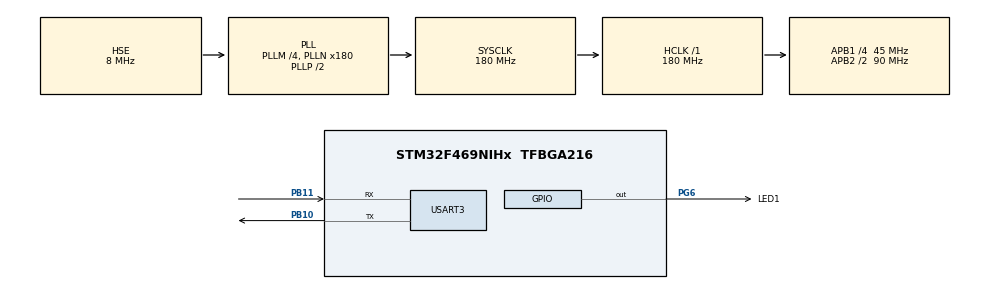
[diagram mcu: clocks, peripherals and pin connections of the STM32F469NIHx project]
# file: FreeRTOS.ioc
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FREERTOS.Tasks01=LEDTask,0,256,StartLEDTask,Default,NULL,Dynamic,NULL,NULL;Task_Info,0,512,StartTask_Info,Default,NULL,Dynamic,NULL,NULL
FREERTOS.configENABLE_BACKWARD_COMPATIBILITY=0
FREERTOS.configGENERATE_RUN_TIME_STATS=1
FREERTOS.configIDLE_SHOULD_YIELD=0
FREERTOS.configQUEUE_REGISTRY_SIZE=0
FREERTOS.configUSE_MUTEXES=0
FREERTOS.configUSE_STATS_FORMATTING_FUNCTIONS=1
FREERTOS.configUSE_TRACE_FACILITY=1
Mcu.Family=STM32F4
Mcu.Name=STM32F469NIHx
Mcu.Package=TFBGA216
NVIC.PriorityGroup=NVIC_PRIORITYGROUP_4
NVIC.TIM6_DAC_IRQn=true\:0\:0\:false\:false\:true\:false\:false
NVIC.TIM7_IRQn=true\:1\:0\:true\:true\:true\:1\:false\:true
NVIC.TimeBase=TIM6_DAC_IRQn
NVIC.TimeBaseIP=TIM6
PA13.Mode=Serial_Wire
PA13.Signal=SYS_JTMS-SWDIO
PA14.Mode=Serial_Wire
PA14.Signal=SYS_JTCK-SWCLK
PB10.Mode=Asynchronous
PB10.Signal=USART3_TX
PB11.Mode=Asynchronous
PB11.Signal=USART3_RX
PC14/OSC32_IN.Mode=LSE-External-Oscillator
PC14/OSC32_IN.Signal=RCC_OSC32_IN
PC15/OSC32_OUT.Mode=LSE-External-Oscillator
PC15/OSC32_OUT.Signal=RCC_OSC32_OUT
PG6.GPIO_Label=LED1
PG6.GPIO_Speed=GPIO_SPEED_FREQ_VERY_HIGH
PG6.Signal=GPIO_Output
PH0/OSC_IN.Mode=HSE-External-Oscillator
PH0/OSC_IN.Signal=RCC_OSC_IN
PH1/OSC_OUT.Mode=HSE-External-Oscillator
PH1/OSC_OUT.Signal=RCC_OSC_OUT
ProjectManager.HeapSize=0x800
ProjectManager.StackSize=0x1000
ProjectManager.TargetToolchain=MDK-ARM V5
RCC.AHBFreq_Value=180000000
RCC.APB1CLKDivider=RCC_HCLK_DIV4
RCC.APB1Freq_Value=45000000
RCC.APB1TimFreq_Value=90000000
RCC.APB2CLKDivider=RCC_HCLK_DIV2
RCC.APB2Freq_Value=90000000
RCC.APB2TimFreq_Value=180000000
RCC.CortexFreq_Value=180000000
RCC.HCLKFreq_Value=180000000
RCC.HSE_VALUE=8000000
RCC.PLLDSIIDF=DSI_PLL_IN_DIV2
RCC.PLLDSINDIV=125
RCC.PLLM=4
RCC.PLLN=180
RCC.PLLQ=6
RCC.PLLR=6
RCC.PLLSAIN=144
RCC.PLLSAIP=RCC_PLLSAIP_DIV6
RCC.PLLSAIQ=2
RCC.PLLSAIRDiv=RCC_PLLSAIDIVR_4
RCC.PLLSourceVirtual=RCC_PLLSOURCE_HSE
RCC.SYSCLKFreq_VALUE=180000000
RCC.SYSCLKSource=RCC_SYSCLKSOURCE_PLLCLK
RCC.USBCLockSelection=RCC_CLK48CLKSOURCE_PLLSAIP
RCC.USBFreq_Value=48000000
RCC.VCOOutputFreq_Value=360000000
TIM7.Period=100
TIM7.Prescaler=18-1
USART3.VirtualMode=VM_ASYNC
VP_FREERTOS_VS_ENABLE.Mode=Enabled
VP_SYS_VS_tim6.Mode=TIM6
VP_TIM7_VS_ClockSourceINT.Mode=Enable_Timer
board=32F469IDISCOVERY

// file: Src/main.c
/**
  ******************************************************************************
  * @file           : main.c
  * @brief          : Main program body
  ******************************************************************************
  * This notice applies to any and all portions of this file
  * that are not between comment pairs USER CODE BEGIN and
  * USER CODE END. Other portions of this file, whether
  * inserted by the user or by software development tools
  * are owned by their respective copyright owners.
  *
  * Copyright (c) 2018 STMicroelectronics International N.V.
  * All rights reserved.
  *
  * Redistribution and use in source and binary forms, with or without
  * modification, are permitted, provided that the following conditions are met:
  *
  * 1. Redistribution of source code must retain the above copyright notice,
  *    this list of conditions and the following disclaimer.
  * 2. Redistributions in binary form must reproduce the above copyright notice,
  *    this list of conditions and the following disclaimer in the documentation
  *    and/or other materials provided with the distribution.
  * 3. Neither the name of STMicroelectronics nor the names of other
  *    contributors to this software may be used to endorse or promote products
  *    derived from this software without specific written permission.
  * 4. This software, including modifications and/or derivative works of this
  *    software, must execute solely and exclusively on microcontroller or
  *    microprocessor devices manufactured by or for STMicroelectronics.
  * 5. Redistribution and use of this software other than as permitted under
  *    this license is void and will automatically terminate your rights under
  *    this license.
  *
  * THIS SOFTWARE IS PROVIDED BY STMICROELECTRONICS AND CONTRIBUTORS "AS IS"
  * AND ANY EXPRESS, IMPLIED OR STATUTORY WARRANTIES, INCLUDING, BUT NOT
  * LIMITED TO, THE IMPLIED WARRANTIES OF MERCHANTABILITY, FITNESS FOR A
  * PARTICULAR PURPOSE AND NON-INFRINGEMENT OF THIRD PARTY INTELLECTUAL PROPERTY
  * RIGHTS ARE DISCLAIMED TO THE FULLEST EXTENT PERMITTED BY LAW. IN NO EVENT
  * SHALL STMICROELECTRONICS OR CONTRIBUTORS BE LIABLE FOR ANY DIRECT, INDIRECT,
  * INCIDENTAL, SPECIAL, EXEMPLARY, OR CONSEQUENTIAL DAMAGES (INCLUDING, BUT NOT
  * LIMITED TO, PROCUREMENT OF SUBSTITUTE GOODS OR SERVICES; LOSS OF USE, DATA,
  * OR PROFITS; OR BUSINESS INTERRUPTION) HOWEVER CAUSED AND ON ANY THEORY OF
  * LIABILITY, WHETHER IN CONTRACT, STRICT LIABILITY, OR TORT (INCLUDING
  * NEGLIGENCE OR OTHERWISE) ARISING IN ANY WAY OUT OF THE USE OF THIS SOFTWARE,
  * EVEN IF ADVISED OF THE POSSIBILITY OF SUCH DAMAGE.
  *
  ******************************************************************************
  */
#include "main.h"
#include "stm32f4xx_hal.h"
#include "cmsis_os.h"

TIM_HandleTypeDef htim7;

UART_HandleTypeDef huart3;

osThreadId LEDTaskHandle;
osThreadId Task_InfoHandle;

/* USER CODE BEGIN PV */
/* Private variables ---------------------------------------------------------*/
extern volatile uint32_t ulHighFrequencyTimerTicks ;
/* USER CODE END PV */

void SystemClock_Config(void);
static void MX_GPIO_Init(void);
void MX_TIM7_Init(void);
static void MX_USART3_UART_Init(void);
void StartLEDTask(void const * argument);
void StartTask_Info(void const * argument);
static void MX_NVIC_Init(void);

/* USER CODE BEGIN PFP */
/* Private function prototypes -----------------------------------------------*/
#ifdef __GNUC__
/* With GCC, small printf (option LD Linker->Libraries->Small printf
   set to 'Yes') calls __io_putchar() */
#define PUTCHAR_PROTOTYPE int __io_putchar(int ch)
#else
#define PUTCHAR_PROTOTYPE int fputc(int ch, FILE *f)
#endif /* __GNUC__ */
/* USER CODE END PFP */

int main(void)
{

  /* MCU Configuration----------------------------------------------------------*/

  /* Reset of all peripherals, Initializes the Flash interface and the Systick. */
  HAL_Init();

  /* Configure the system clock */
  SystemClock_Config();

  /* Initialize all configured peripherals */
  MX_GPIO_Init();
  MX_TIM7_Init();
  MX_USART3_UART_Init();

  /* Initialize interrupts */
  MX_NVIC_Init();
  /* USER CODE BEGIN 2 */
  HAL_TIM_Base_Start_IT(&htim7);
  /* USER CODE END 2 */

  /* Create the thread(s) */
  /* definition and creation of LEDTask */
  osThreadDef(LEDTask, StartLEDTask, osPriorityNormal, 0, 256);
  LEDTaskHandle = osThreadCreate(osThread(LEDTask), NULL);

  /* definition and creation of Task_Info */
  osThreadDef(Task_Info, StartTask_Info, osPriorityNormal, 0, 512);
  Task_InfoHandle = osThreadCreate(osThread(Task_Info), NULL);

  /* Start scheduler */
  osKernelStart();

  /* We should never get here as control is now taken by the scheduler */

  /* Infinite loop */
  while (1)
  {

  }

}

void SystemClock_Config(void)
{

  RCC_OscInitTypeDef RCC_OscInitStruct;
  RCC_ClkInitTypeDef RCC_ClkInitStruct;

    /**Configure the main internal regulator output voltage
    */
  __HAL_RCC_PWR_CLK_ENABLE();

  __HAL_PWR_VOLTAGESCALING_CONFIG(PWR_REGULATOR_VOLTAGE_SCALE1);

    /**Initializes the CPU, AHB and APB busses clocks
    */
  RCC_OscInitStruct.OscillatorType = RCC_OSCILLATORTYPE_HSE;
  RCC_OscInitStruct.HSEState = RCC_HSE_ON;
  RCC_OscInitStruct.PLL.PLLState = RCC_PLL_ON;
  RCC_OscInitStruct.PLL.PLLSource = RCC_PLLSOURCE_HSE;
  RCC_OscInitStruct.PLL.PLLM = 4;
  RCC_OscInitStruct.PLL.PLLN = 180;
  RCC_OscInitStruct.PLL.PLLP = RCC_PLLP_DIV2;
  RCC_OscInitStruct.PLL.PLLQ = 6;
  RCC_OscInitStruct.PLL.PLLR = 6;
  if (HAL_RCC_OscConfig(&RCC_OscInitStruct) != HAL_OK)
  {
    _Error_Handler(__FILE__, __LINE__);
  }

    /**Activate the Over-Drive mode
    */
  if (HAL_PWREx_EnableOverDrive() != HAL_OK)
  {
    _Error_Handler(__FILE__, __LINE__);
  }

    /**Initializes the CPU, AHB and APB busses clocks
    */
  RCC_ClkInitStruct.ClockType = RCC_CLOCKTYPE_HCLK|RCC_CLOCKTYPE_SYSCLK
                              |RCC_CLOCKTYPE_PCLK1|RCC_CLOCKTYPE_PCLK2;
  RCC_ClkInitStruct.SYSCLKSource = RCC_SYSCLKSOURCE_PLLCLK;
  RCC_ClkInitStruct.AHBCLKDivider = RCC_SYSCLK_DIV1;
  RCC_ClkInitStruct.APB1CLKDivider = RCC_HCLK_DIV4;
  RCC_ClkInitStruct.APB2CLKDivider = RCC_HCLK_DIV2;

  if (HAL_RCC_ClockConfig(&RCC_ClkInitStruct, FLASH_LATENCY_5) != HAL_OK)
  {
    _Error_Handler(__FILE__, __LINE__);
  }

    /**Configure the Systick interrupt time
    */
  HAL_SYSTICK_Config(HAL_RCC_GetHCLKFreq()/1000);

    /**Configure the Systick
    */
  HAL_SYSTICK_CLKSourceConfig(SYSTICK_CLKSOURCE_HCLK);

  /* SysTick_IRQn interrupt configuration */
  HAL_NVIC_SetPriority(SysTick_IRQn, 15, 0);
}

/**
  * @brief NVIC Configuration.
  * @retval None
  */
static void MX_NVIC_Init(void)
{
  /* TIM7_IRQn interrupt configuration */
  HAL_NVIC_SetPriority(TIM7_IRQn, 1, 0);
  HAL_NVIC_EnableIRQ(TIM7_IRQn);
}

/* TIM7 init function */
void MX_TIM7_Init(void)
{

  TIM_MasterConfigTypeDef sMasterConfig;

  htim7.Instance = TIM7;
  htim7.Init.Prescaler = 18-1;
  htim7.Init.CounterMode = TIM_COUNTERMODE_UP;
  htim7.Init.Period = 100;
  if (HAL_TIM_Base_Init(&htim7) != HAL_OK)
  {
    _Error_Handler(__FILE__, __LINE__);
  }

  sMasterConfig.MasterOutputTrigger = TIM_TRGO_RESET;
  sMasterConfig.MasterSlaveMode = TIM_MASTERSLAVEMODE_DISABLE;
  if (HAL_TIMEx_MasterConfigSynchronization(&htim7, &sMasterConfig) != HAL_OK)
  {
    _Error_Handler(__FILE__, __LINE__);
  }

}

/* USART3 init function */
static void MX_USART3_UART_Init(void)
{

  huart3.Instance = USART3;
  huart3.Init.BaudRate = 115200;
  huart3.Init.WordLength = UART_WORDLENGTH_8B;
  huart3.Init.StopBits = UART_STOPBITS_1;
  huart3.Init.Parity = UART_PARITY_NONE;
  huart3.Init.Mode = UART_MODE_TX_RX;
  huart3.Init.HwFlowCtl = UART_HWCONTROL_NONE;
  huart3.Init.OverSampling = UART_OVERSAMPLING_16;
  if (HAL_UART_Init(&huart3) != HAL_OK)
  {
    _Error_Handler(__FILE__, __LINE__);
  }

}

/** Configure pins as
        * Analog
        * Input
        * Output
        * EVENT_OUT
        * EXTI
*/
static void MX_GPIO_Init(void)
{

  GPIO_InitTypeDef GPIO_InitStruct;

  /* GPIO Ports Clock Enable */
  __HAL_RCC_GPIOA_CLK_ENABLE();
  __HAL_RCC_GPIOC_CLK_ENABLE();
  __HAL_RCC_GPIOH_CLK_ENABLE();
  __HAL_RCC_GPIOG_CLK_ENABLE();
  __HAL_RCC_GPIOB_CLK_ENABLE();

  /*Configure GPIO pin Output Level */
  HAL_GPIO_WritePin(LED1_GPIO_Port, LED1_Pin, GPIO_PIN_RESET);

  /*Configure GPIO pin : LED1_Pin */
  GPIO_InitStruct.Pin = LED1_Pin;
  GPIO_InitStruct.Mode = GPIO_MODE_OUTPUT_PP;
  GPIO_InitStruct.Pull = GPIO_NOPULL;
  GPIO_InitStruct.Speed = GPIO_SPEED_FREQ_VERY_HIGH;
  HAL_GPIO_Init(LED1_GPIO_Port, &GPIO_InitStruct);

}

/* USER CODE BEGIN 4 */
/**
  * @brief  Retargets the C library printf function to the USART.
  * @param  None
  * @retval None
  */
PUTCHAR_PROTOTYPE
{
  /* Place your implementation of fputc here */
  /* e.g. write a character to the USART1 and Loop until the end of transmission */
  HAL_UART_Transmit(&huart3, (uint8_t *)&ch, 1, 0xFFFF);

  return ch;
}
/* USER CODE END 4 */

/* StartLEDTask function */
void StartLEDTask(void const * argument)
{

  /* USER CODE BEGIN 5 */
  /* Infinite loop */
  for(;;)
  {
		HAL_GPIO_TogglePin(LED1_GPIO_Port, LED1_Pin);
    osDelay(1000);
  }
  /* USER CODE END 5 */
}

/* StartTask_Info function */
void StartTask_Info(void const * argument)
{
  /* USER CODE BEGIN StartTask_Info */
	uint8_t List_Buff[256];
	uint8_t Stats_Buff[256];
  /* Infinite loop */
  for(;;)
  {

		printf("=================================================\r\n");
    printf("任务名    任务状态    优先级    剩余栈    任务序号\r\n");
    vTaskList((char *)&List_Buff);
    printf("%s\r\n", List_Buff);

    printf("\r\n任务名    运行计数    使用率\r\n");
    vTaskGetRunTimeStats((char *)&Stats_Buff);
    printf("%s\r\n", Stats_Buff);
    osDelay(2000);
  }
  /* USER CODE END StartTask_Info */
}

void HAL_TIM_PeriodElapsedCallback(TIM_HandleTypeDef *htim)
{
  if (htim->Instance == TIM6) {
    HAL_IncTick();
  }
  /* USER CODE BEGIN Callback 1 */
  if (htim->Instance == TIM7) {
      ulHighFrequencyTimerTicks++;
  }
  /* USER CODE END Callback 1 */
}

void _Error_Handler(char *file, int line)
{
  while(1)
  {
  }
}

/************************ (C) COPYRIGHT STMicroelectronics *****END OF FILE****/

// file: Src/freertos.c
/**
  ******************************************************************************
  * File Name          : freertos.c
  * Description        : Code for freertos applications
  ******************************************************************************
  * This notice applies to any and all portions of this file
  * that are not between comment pairs USER CODE BEGIN and
  * USER CODE END. Other portions of this file, whether
  * inserted by the user or by software development tools
  * are owned by their respective copyright owners.
  *
  * Copyright (c) 2018 STMicroelectronics International N.V.
  * All rights reserved.
  *
  * Redistribution and use in source and binary forms, with or without
  * modification, are permitted, provided that the following conditions are met:
  *
  * 1. Redistribution of source code must retain the above copyright notice,
  *    this list of conditions and the following disclaimer.
  * 2. Redistributions in binary form must reproduce the above copyright notice,
  *    this list of conditions and the following disclaimer in the documentation
  *    and/or other materials provided with the distribution.
  * 3. Neither the name of STMicroelectronics nor the names of other
  *    contributors to this software may be used to endorse or promote products
  *    derived from this software without specific written permission.
  * 4. This software, including modifications and/or derivative works of this
  *    software, must execute solely and exclusively on microcontroller or
  *    microprocessor devices manufactured by or for STMicroelectronics.
  * 5. Redistribution and use of this software other than as permitted under
  *    this license is void and will automatically terminate your rights under
  *    this license.
  *
  * THIS SOFTWARE IS PROVIDED BY STMICROELECTRONICS AND CONTRIBUTORS "AS IS"
  * AND ANY EXPRESS, IMPLIED OR STATUTORY WARRANTIES, INCLUDING, BUT NOT
  * LIMITED TO, THE IMPLIED WARRANTIES OF MERCHANTABILITY, FITNESS FOR A
  * PARTICULAR PURPOSE AND NON-INFRINGEMENT OF THIRD PARTY INTELLECTUAL PROPERTY
  * RIGHTS ARE DISCLAIMED TO THE FULLEST EXTENT PERMITTED BY LAW. IN NO EVENT
  * SHALL STMICROELECTRONICS OR CONTRIBUTORS BE LIABLE FOR ANY DIRECT, INDIRECT,
  * INCIDENTAL, SPECIAL, EXEMPLARY, OR CONSEQUENTIAL DAMAGES (INCLUDING, BUT NOT
  * LIMITED TO, PROCUREMENT OF SUBSTITUTE GOODS OR SERVICES; LOSS OF USE, DATA,
  * OR PROFITS; OR BUSINESS INTERRUPTION) HOWEVER CAUSED AND ON ANY THEORY OF
  * LIABILITY, WHETHER IN CONTRACT, STRICT LIABILITY, OR TORT (INCLUDING
  * NEGLIGENCE OR OTHERWISE) ARISING IN ANY WAY OUT OF THE USE OF THIS SOFTWARE,
  * EVEN IF ADVISED OF THE POSSIBILITY OF SUCH DAMAGE.
  *
  ******************************************************************************
  */

#include "FreeRTOS.h"
#include "task.h"

/* USER CODE BEGIN Includes */
#include "main.h"
#include "stm32f4xx_hal.h"
/* USER CODE END Includes */

/* USER CODE BEGIN Variables */
volatile uint32_t ulHighFrequencyTimerTicks ;
/* USER CODE END Variables */

/* Hook prototypes */
void configureTimerForRunTimeStats(void);
unsigned long getRunTimeCounterValue(void);

/* USER CODE BEGIN 1 */
/* Functions needed when configGENERATE_RUN_TIME_STATS is on */
__weak void configureTimerForRunTimeStats(void)
{
 ulHighFrequencyTimerTicks = 0UL;
}

__weak unsigned long getRunTimeCounterValue(void)
{
return ulHighFrequencyTimerTicks;
}
/* USER CODE END 1 */

/************************ (C) COPYRIGHT STMicroelectronics *****END OF FILE****/
